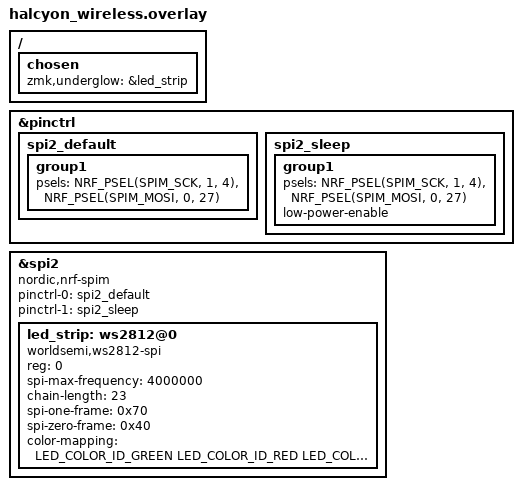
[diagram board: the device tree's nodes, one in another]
/*
 * Copyright (c) 2026 Splitkb.com
 *
 * SPDX-License-Identifier: MIT
 */

#include <dt-bindings/led/led.h>

/ {
    chosen {
        zmk,underglow = &led_strip;
    };
};

&pinctrl {
    spi2_default: spi2_default {
        group1 {
            psels = <NRF_PSEL(SPIM_SCK, 1, 4)>,
                    <NRF_PSEL(SPIM_MOSI, 0, 27)>;
        };
    };

    spi2_sleep: spi2_sleep {
        group1 {
            psels = <NRF_PSEL(SPIM_SCK, 1, 4)>,
                    <NRF_PSEL(SPIM_MOSI, 0, 27)>;
            low-power-enable;
        };
    };
};

&spi2 {
    compatible = "nordic,nrf-spim";
    status = "okay";

    pinctrl-0 = <&spi2_default>;
    pinctrl-1 = <&spi2_sleep>;
    pinctrl-names = "default", "sleep";

    led_strip: ws2812@0 {
        compatible = "worldsemi,ws2812-spi";

        /* SPI */
        reg = <0>; /* ignored, but necessary for SPI bindings */
        spi-max-frequency = <4000000>;

        /* WS2812 */
        chain-length = <23>; /* arbitrary; change at will */
        spi-one-frame = <0x70>;
        spi-zero-frame = <0x40>;

        color-mapping = <LED_COLOR_ID_GREEN 
                LED_COLOR_ID_RED 
                LED_COLOR_ID_BLUE>;
    };
};
